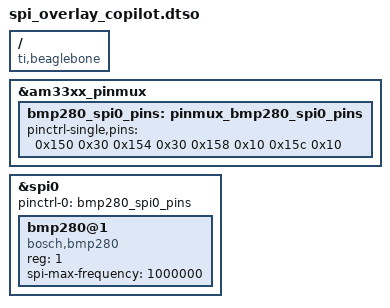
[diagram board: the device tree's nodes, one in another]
/dts-v1/;
/plugin/;

/ {
    compatible = "ti,beaglebone", "ti,beaglebone-black";

    fragment@0 {
        target = <&am33xx_pinmux>;
        __overlay__ {
            bmp280_spi0_pins: pinmux_bmp280_spi0_pins {
                pinctrl-single,pins = <
                    0x150 0x30  /* spi0_sclk  -> mode 0, output, pullup */
                    0x154 0x30  /* spi0_d0    -> mode 0, input, pullup */
                    0x158 0x10  /* spi0_d1    -> mode 0, output */
                    0x15c 0x10  /* spi0_cs1   -> mode 0, output */
                >;
            };
        };
    };

    fragment@1 {
        target = <&spi0>;
        __overlay__ {
            #address-cells = <1>;
            #size-cells = <0>;
            status = "okay";
            pinctrl-names = "default";
            pinctrl-0 = <&bmp280_spi0_pins>;

            bmp280@1 {
                compatible = "bosch,bmp280";
                reg = <1>;  /* Chip select 1 */
                spi-max-frequency = <1000000>;
                status = "okay";
            };
        };
    };
};
